# R7FA0L107 register map
Vendor: Renesas Electronics Corporation; Series: RA0; File version: 1.10.01
CPU: CM23 r1p0, little endian, no MPU, no FPU, VTOR, 2 interrupt priority bits, 64 interrupts
Registers are 16-bit, read-write, reset 0x0 unless marked. A register's access mark holds for its fields unless they carry their own. Offsets are from the block's base; [hi:lo] are bit positions; {n}, {i} and the like mark numbered series; 'fields as' and 'values as' point back to an identical list.

## BUS — BUS Control
Base 0x40003000
0x1008 BUSMCNTSYS — Master Bus Control Register SYS
  [15] IERES — Ignore Error Responses
    0=A bus error is reported; 1=A bus error is not reported
0x100C BUSMCNTDMA — Master Bus Control Register DMA
  fields as BUSMCNTSYS
0x1820 BUS3ERRADD 32-bit ro reset not defined — Bus Error Address Register 3
  [31:0] BERAD — Bus Error Address
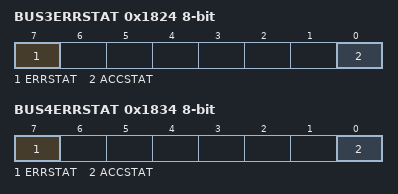
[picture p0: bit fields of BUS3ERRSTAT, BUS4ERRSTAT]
0x1824 BUS3ERRSTAT 8-bit ro (reset mask 0xFE) — BUS Error Status Register 3
  [7] ERRSTAT — Bus Error Status flag
    0=No bus error occurred; 1=Bus error occurred
  [0] ACCSTAT — Error Access Status flag
    0=Read access; 1=Write access
0x1830 BUS4ERRADD 32-bit ro reset not defined — Bus Error Address Register 4
  [31:0] BERAD — Bus Error Address
0x1834 BUS4ERRSTAT 8-bit ro (reset mask 0xFE) — BUS Error Status Register 4
  fields as BUS3ERRSTAT

## DTC — Data Transfer Controller
Base 0x40005400
0x00 DTCCR 8-bit reset 0x8 — DTC Control Register
  [4] RRS — DTC Transfer Information Read Skip Enable
    0=Transfer information read is not skipped; 1=Transfer information read is skipped when vector numbers match
0x04 DTCVBR 32-bit — DTC Vector Base Register
0x0C DTCST 8-bit — DTC Module Start Register
  [0] DTCST — DTC Module Start
    0=DTC module stopped; 1=DTC module started
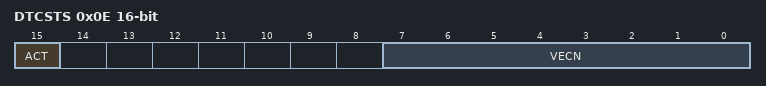
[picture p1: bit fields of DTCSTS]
0x0E DTCSTS ro — DTC Status Register
  [15] ACT — DTC Active Flag
    0=DTC transfer operation is not in progress; 1=DTC transfer operation is in progress
  [7:0] VECN — DTC-Activating Vector Number Monitoring

## DBG — Debug Function
Base 0x4001B000
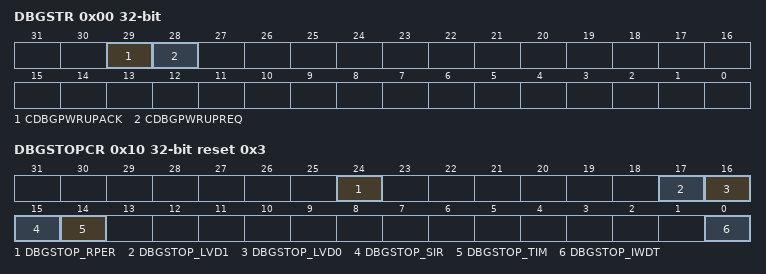
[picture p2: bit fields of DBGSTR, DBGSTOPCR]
0x00 DBGSTR 32-bit ro — Debug Status Register
  [29] CDBGPWRUPACK — Debug Power-up Acknowledge
    0=Debug power-up request is not acknowledged; 1=Debug power-up request is acknowledged
  [28] CDBGPWRUPREQ — Debug Power-up Request
    0=OCD emulator is not requesting debug power up; 1=OCD emulator is requesting debug power up
0x10 DBGSTOPCR 32-bit reset 0x3 — Debug Stop Control Register
  [24] DBGSTOP_RPER — Mask Bit for SRAM Parity Error Reset/Interrupt
    0=Enable SRAM parity error reset/interrupt; 1=Mask SRAM parity error reset/interrupt
  [17] DBGSTOP_LVD1 — Mask Bit for LVD1 Reset/Interrupt
    0=Enable LVD1 reset/interrupt; 1=Mask LVD1 reset/interrupt
  [16] DBGSTOP_LVD0 — Mask Bit for LVD0 Reset
    0=Enable LVD0 reset; 1=Mask LVD0 reset
  [15] DBGSTOP_SIR — Mask Bit for SAU, IICA, UARTA, PORT_IRQ0-7 Reset/Interrupt in the OCD brake mode. In the OCD break mode, the reset/interrupt is masked and each operation is stopped.
    0=Enable SAU, IICA, UARTA, PORT_IRQ0 to 7 reset/interrupt; 1=Mask SAU, IICA, UARTA, PORT_IRQ0 to 7 reset/interrupt
  [14] DBGSTOP_TIM
    0=Enable RTC, TAU, TML32 reset/interrupt; 1=Mask RTC, TAU, TML32 reset/interrupt
  [0] DBGSTOP_IWDT — Mask Bit for IWDT Reset/Interrupt in the OCD Run Mode
    0=Enable IWDT reset/interrupt; 1=Mask IWDT reset/interrupt and stop IWDT counter

## ELC — Event Link Controller
Base 0x40041000
0x00 ELCR 8-bit — Event Link Controller Register
  [7] ELCON — All Event Link Enable
    0=All the event link operations are disabled; 1=All the event link operations are enabled
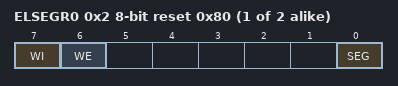
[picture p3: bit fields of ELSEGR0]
{0x2+2i} ELSEGR{i} (i=0..1) 8-bit reset 0x80 — Event Link Software Event Generation Register {i}
  [7] WI wo — ELSEGR Register Write Disable
    0=Write to ELSEGR register enabled; 1=Write to ELSEGR register disabled
  [6] WE — SEG Bit Write Enable
    0=Write to SEG bit disabled; 1=Write to SEG bit enabled
  [0] SEG wo — Software Event Generation
    0=Not generates a software event; 1=Generates a software event
0x58 ELSR18 — Event Link Setting Register 18
  [5:0] ELS — Event Link Select
{0x10+4i} ELSR{i} (i=23..28) — Event Link Setting Register {i}
  [5:0] ELS — Event Link Select
